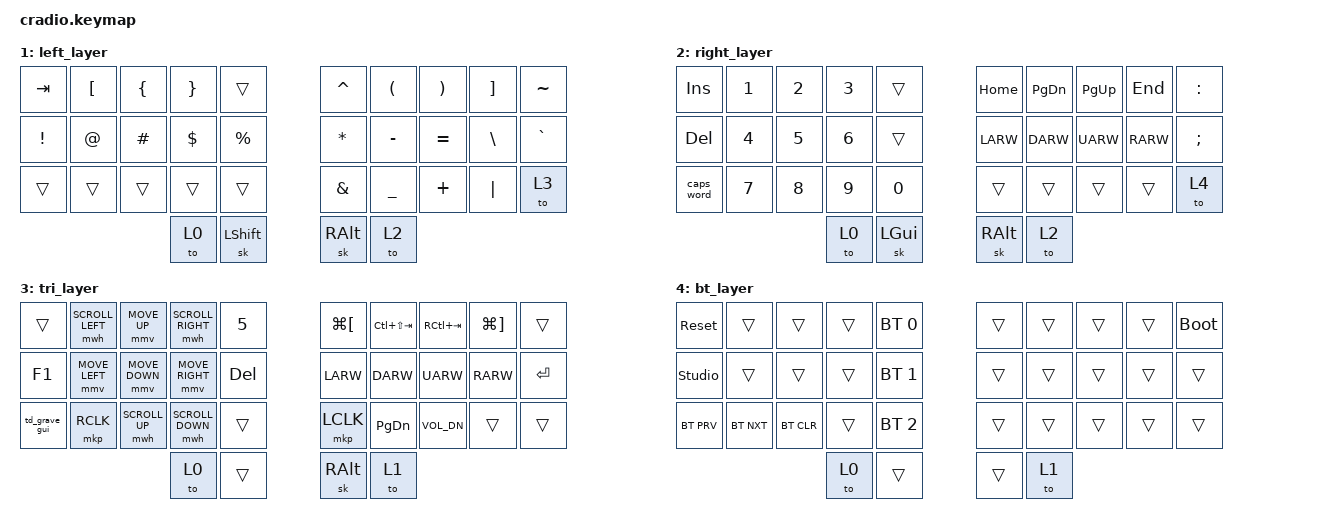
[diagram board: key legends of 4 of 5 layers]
// Copyright (c) 2022 The ZMK Contributors
// SPDX-License-Identifier: MIT

#include <behaviors.dtsi>
#include <dt-bindings/zmk/keys.h>
#include <dt-bindings/zmk/bt.h>
#include <dt-bindings/zmk/mouse.h>

// Home row mods macro
#define HRML(k1,k2,k3,k4) &ht LSHFT k1  &ht LALT k2  &ht LCTRL k3  &ht LGUI k4
#define HRMR(k1,k2,k3,k4) &ht RGUI k1  &ht RCTRL k2  &ht RALT k3  &ht RSHFT k4

&mmv {
    time-to-max-speed-ms = <680>;
    acceleration-exponent = <2>;
};

/ {
    behaviors {
        ht: hold_tap {
            label = "hold_tap";
            compatible = "zmk,behavior-hold-tap";
            #binding-cells = <2>;
            flavor = "tap-preferred";
            tapping-term-ms = <220>;
            quick-tap-ms = <150>;
            require-prior-idle-ms = <100>;
            bindings = <&kp>, <&kp>;
        };

        td_comma_minus: td_comma_minus {
            compatible = "zmk,behavior-tap-dance";
            label = "TD_COMMA_MINUS";
            #binding-cells = <0>;
            tapping-term-ms = <150>;
            bindings = <&kp COMMA>, <&kp MINUS>;
        };

        td_dot_excl: td_dot_excl {
            compatible = "zmk,behavior-tap-dance";
            label = "TD_DOT_EXCL";
            #binding-cells = <0>;
            tapping-term-ms = <150>;
            bindings = <&kp DOT>, <&kp EXCL>;
        };

        td_slash_underscore: td_slash_underscore {
            compatible = "zmk,behavior-tap-dance";
            label = "TD_SLASH_UNDERSCORE";
            #binding-cells = <0>;
            tapping-term-ms = <150>;
            bindings = <&kp FSLH>, <&kp UNDER>;
        };

        td_grave_gui: td_grave_gui {
            compatible = "zmk,behavior-tap-dance";
            label = "TD_GRAVE_GUI";
            #binding-cells = <0>;
            tapping-term-ms = <150>;
            bindings = <&kp GRAVE>, <&kp LG(GRAVE)>;
        };
    };

    keymap {
        compatible = "zmk,keymap";
        default_layer {
            bindings = <
        //╭──────────┬──────────┬──────────┬──────────┬──────────╮   ╭──────────┬──────────┬──────────┬──────────┬──────────╮
        //│  Q       │  W       │  E       │  R       │  T       │   │  Y       │  U       │  I       │  O       │  P       │
            &kp Q      &kp W      &kp E      &kp R      &kp T          &kp Y      &kp U      &kp I      &kp O      &kp P
        //├──────────┼──────────┼──────────┼──────────┼──────────┤   ├──────────┼──────────┼──────────┼──────────┼──────────┤
        //│  A       │  S       │  D       │  F       │  G       │   │  H       │  J       │  K       │  L       │ ' "      │
            HRML(A,        S,         D,         F)     &kp G          &kp H      HRMR(J,        K,         L,        SQT)
        //├──────────┼──────────┼──────────┼──────────┼──────────┤   ├──────────┼──────────┼──────────┼──────────┼──────────┤
        //│  Z       │  X       │  C       │  V       │  B       │   │  N       │  M       │ , / -    │ . / !    │ / / _    │
            &kp Z      &kp X      &kp C      &kp V      &kp B          &kp N      &kp M      &td_comma_minus &td_dot_excl &td_slash_underscore
        //╰──────────┴──────────┴──────────┼──────────┼──────────┤   ├──────────┼──────────┼──────────┴──────────┴──────────╯
                                            &to 1      &kp ENTER     &kp SPACE  &kp BSPC
        //                                 ╰──────────┴──────────╯   ╰──────────┴──────────╯
            >;
        };

        left_layer {
            bindings = <
        //╭──────────┬──────────┬──────────┬──────────┬──────────╮   ╭──────────┬──────────┬──────────┬──────────┬──────────╮
        //│  TAB     │  [       │  {       │  }       │          │   │  ^       │  (       │  )       │  ]       │  ~       │
            &kp TAB   &kp LBKT   &kp LBRC   &kp RBRC   &trans         &kp CARET  &kp LPAR   &kp RPAR   &kp RBKT   &kp TILDE
        //├──────────┼──────────┼──────────┼──────────┼──────────┤   ├──────────┼──────────┼──────────┼──────────┼──────────┤
        //│  !       │  @       │  #       │  $       │  %       │   │  *       │  -       │  =       │  \       │  `       │
            &kp EXCL   &kp AT     &kp HASH   &kp DLLR   &kp PRCNT      &kp ASTRK  &kp MINUS  &kp EQUAL  &kp BSLH   &kp GRAVE
        //├──────────┼──────────┼──────────┼──────────┼──────────┤   ├──────────┼──────────┼──────────┼──────────┼──────────┤
        //│          │          │          │          │          │   │  &       │  _       │  +       │  │       │  TO 3    │
            &trans     &trans     &trans     &trans     &trans         &kp AMPS   &kp UNDER  &kp PLUS   &kp PIPE   &to 3
        //╰──────────┴──────────┴──────────┼──────────┼──────────┤   ├──────────┼──────────┼──────────┴──────────┴──────────╯
                                             &to 0      &sk LSHIFT     &sk RALT   &to 2
        //                                 ╰──────────┴──────────╯   ╰──────────┴──────────╯
            >;
        };

        right_layer {
            bindings = <
        //╭──────────┬──────────┬──────────┬──────────┬──────────╮   ╭──────────┬──────────┬──────────┬──────────┬──────────╮
        //│ INSERT   │  1       │  2       │  3       │          │   │ HOME     │ PAGE DN  │ PAGE UP  │ END      │  :       │
            &kp INS    &kp N1     &kp N2     &kp N3     &trans         &kp HOME   &kp PG_DN  &kp PG_UP  &kp END    &kp COLON
        //├──────────┼──────────┼──────────┼──────────┼──────────┤   ├──────────┼──────────┼──────────┼──────────┼──────────┤
        //│ DELETE   │  4       │  5       │  6       │          │   │ LEFT     │ DOWN     │ UP       │ RIGHT    │  ;       │
            &kp DEL    &kp N4     &kp N5     &kp N6     &trans         &kp LARW   &kp DARW   &kp UARW   &kp RARW   &kp SEMI
        //├──────────┼──────────┼──────────┼──────────┼──────────┤   ├──────────┼──────────┼──────────┼──────────┼──────────┤
        //│ CAPS     │  7       │  8       │  9       │  0       │   │          │          │          │          │  TO 4    │
           &caps_word  &kp N7     &kp N8     &kp N9     &kp N0         &trans     &trans     &trans     &trans     &to 4
        //╰──────────┴──────────┴──────────┼──────────┼──────────┤   ├──────────┼──────────┼──────────┴──────────┴──────────╯
                                             &to 0      &sk LGUI       &sk RALT   &to 2
        //                                 ╰──────────┴──────────╯   ╰──────────┴──────────╯
            >;
        };

        tri_layer {
            bindings = <
        //╭──────────┬──────────────┬──────────────┬──────────────┬──────────╮   ╭──────────┬─────────────┬─────────────┬─────────────┬──────────╮
        //│          │ SCROLL LEFT  │  MOVE UP     │ SCROLL RIGHT │  5       │   │ LG-[     │ LC(LS(TAB)) │ RC(TAB)     │ LG-]        │          │
            &trans     &mwh SCROLL_LEFT &mmv MOVE_UP &mwh SCROLL_RIGHT &kp N5        &kp LG(LBKT) &kp LC(LS(TAB)) &kp RC(TAB) &kp LG(RBKT) &trans
        //├──────────┼──────────────┼──────────────┼──────────────┼──────────┤   ├──────────┼───────────┬───────────┬───────────┬──────────┤
        //│  F1      │  MOVE LEFT   │  MOVE DOWN   │  MOVE RIGHT  │  DELETE  │   │ LEFT     │ DOWN      │ UP        │ RIGHT     │  ENTER   │
            &kp F1     &mmv MOVE_LEFT &mmv MOVE_DOWN &mmv MOVE_RIGHT &kp DEL       &kp LARW   &kp DARW   &kp UARW   &kp RARW   &kp ENTER
        //├──────────┼──────────────┼──────────────┼──────────────┼──────────┤   ├──────────┼───────────┬───────────┬───────────┬──────────┤
        //│ ` / GUI  │  R CLICK     │ SCROLL UP    │ SCROLL DOWN  │          │   │ L CLICK  │ PAGE DN   │ VOL DN    │           │          │
            &td_grave_gui &mkp RCLK   &mwh SCROLL_UP &mwh SCROLL_DOWN &trans        &mkp LCLK  &kp PG_DN  &kp C_VOL_DN &trans     &trans
        //╰──────────┴──────────────┴──────────────┼──────────┼──────────┤   ├──────────┼──────────┼──────────┴──────────┴──────────╯
                                             &to 0      &trans         &sk RALT   &to 1
        //                                 ╰──────────┴──────────╯   ╰──────────┴──────────╯
            >;
        };

        bt_layer {
            bindings = <
        //╭──────────┬──────────┬──────────┬──────────┬────────────╮   ╭──────────┬──────────┬──────────┬──────────┬────────────╮
        //│ RESET    │          │          │          │PROFILE 0   │   │          │          │          │          │BOOTLOADER  │
            &sys_reset &trans    &trans     &trans     &bt BT_SEL 0     &trans     &trans     &trans     &trans     &bootloader
        //├──────────┼──────────┼──────────┼──────────┼────────────┤   ├──────────┼──────────┼──────────┼──────────┼────────────┤
        //│ UNLOCK   │          │          │          │PROFILE 1   │   │          │          │          │          │            │
            &studio_unlock &trans &trans    &trans     &bt BT_SEL 1     &trans     &trans     &trans     &trans     &trans
        //├──────────┼──────────┼──────────┼──────────┼────────────┤   ├──────────┼──────────┼──────────┼──────────┼────────────┤
        //│ BT PREV  │ BT NEXT  │ CLEAR BT │          │PROFILE 2   │   │          │          │          │          │            │
            &bt BT_PRV &bt BT_NXT &bt BT_CLR &trans   &bt BT_SEL 2     &trans     &trans     &trans     &trans     &trans
        //╰──────────┴──────────┴──────────┼──────────┼──────────┤   ├──────────┼──────────┼──────────┴──────────┴──────────╯
                                             &to 0      &trans         &trans     &to 1
        //                                 ╰──────────┴──────────╯   ╰──────────┴──────────╯
            >;
        };
    };
};
